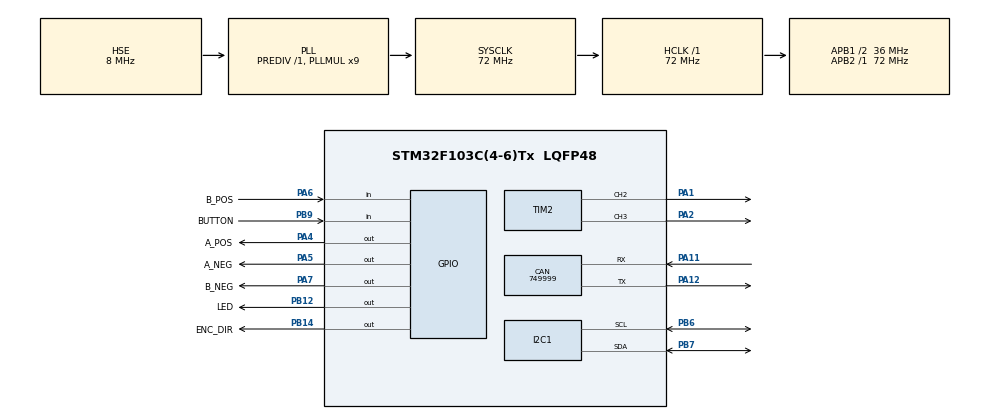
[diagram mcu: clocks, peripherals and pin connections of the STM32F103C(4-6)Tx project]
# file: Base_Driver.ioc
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CAN.BS1=CAN_BS1_1TQ
CAN.BS2=CAN_BS2_1TQ
CAN.CalculateBaudRate=749999
CAN.CalculateTimeBit=1333
CAN.CalculateTimeQuantum=444.44444444444446
Mcu.Family=STM32F1
Mcu.Name=STM32F103C(4-6)Tx
Mcu.Package=LQFP48
NVIC.PriorityGroup=NVIC_PRIORITYGROUP_4
PA1.Signal=S_TIM2_CH2
PA11.Mode=CAN_Activate
PA11.Signal=CAN_RX
PA12.Mode=CAN_Activate
PA12.Signal=CAN_TX
PA13.Mode=Serial_Wire
PA13.Signal=SYS_JTMS-SWDIO
PA14.Mode=Serial_Wire
PA14.Signal=SYS_JTCK-SWCLK
PA2.Signal=S_TIM2_CH3
PA4.GPIO_Label=A_POS
PA4.Signal=GPIO_Output
PA5.GPIO_Label=A_NEG
PA5.Signal=GPIO_Output
PA6.GPIO_Label=B_POS
PA6.Signal=GPIO_Input
PA7.GPIO_Label=B_NEG
PA7.Signal=GPIO_Output
PB12.GPIO_Label=LED
PB12.Signal=GPIO_Output
PB14.GPIO_Label=ENC_DIR
PB14.Signal=GPIO_Output
PB6.Mode=I2C
PB6.Signal=I2C1_SCL
PB7.Mode=I2C
PB7.Signal=I2C1_SDA
PB9.GPIO_Label=BUTTON
PB9.Signal=GPIO_Input
PD0-OSC_IN.Mode=HSE-External-Oscillator
PD0-OSC_IN.Signal=RCC_OSC_IN
PD1-OSC_OUT.Mode=HSE-External-Oscillator
PD1-OSC_OUT.Signal=RCC_OSC_OUT
ProjectManager.HeapSize=0x200
ProjectManager.StackSize=0x400
ProjectManager.TargetToolchain=STM32CubeIDE
RCC.AHBFreq_Value=72000000
RCC.APB1CLKDivider=RCC_HCLK_DIV2
RCC.APB1Freq_Value=36000000
RCC.APB1TimFreq_Value=72000000
RCC.APB2Freq_Value=72000000
RCC.APB2TimFreq_Value=72000000
RCC.HCLKFreq_Value=72000000
RCC.PLLMUL=RCC_PLL_MUL9
RCC.PLLSourceVirtual=RCC_PLLSOURCE_HSE
RCC.SYSCLKFreq_VALUE=72000000
RCC.SYSCLKSource=RCC_SYSCLKSOURCE_PLLCLK
RCC.USBFreq_Value=72000000
SH.S_TIM2_CH2.0=TIM2_CH2,PWM Generation2 CH2
SH.S_TIM2_CH3.0=TIM2_CH3,PWM Generation3 CH3
TIM2.Channel-PWM\ Generation2\ CH2=TIM_CHANNEL_2
TIM2.Channel-PWM\ Generation3\ CH3=TIM_CHANNEL_3
VP_TIM2_VS_ClockSourceINT.Mode=Internal
board=custom

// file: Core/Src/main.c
/* USER CODE BEGIN Header */
/**
  ******************************************************************************
  * @file           : main.c
  * @brief          : Main program body
  ******************************************************************************
  * @attention
  *
  * Copyright (c) 2024 STMicroelectronics.
  * All rights reserved.
  *
  * This software is licensed under terms that can be found in the LICENSE file
  * in the root directory of this software component.
  * If no LICENSE file comes with this software, it is provided AS-IS.
  *
  ******************************************************************************
  */
/* USER CODE END Header */
#include "main.h"
#include "as5600.h"
#include <string.h>

CAN_HandleTypeDef hcan;

I2C_HandleTypeDef hi2c1;

TIM_HandleTypeDef htim2;

void SystemClock_Config(void);
static void MX_GPIO_Init(void);
static void MX_CAN_Init(void);
static void MX_I2C1_Init(void);
static void MX_TIM2_Init(void);

int main(void)
{

  /* USER CODE BEGIN 1 */
	float angle = 0;
  /* USER CODE END 1 */

  /* MCU Configuration--------------------------------------------------------*/

  /* Reset of all peripherals, Initializes the Flash interface and the Systick. */
  HAL_Init();

  /* Configure the system clock */
  SystemClock_Config();

  /* Initialize all configured peripherals */
  MX_GPIO_Init();
  MX_CAN_Init();
  MX_I2C1_Init();
  MX_TIM2_Init();

  /* Infinite loop */
  while (1)
  {
	  angle = AS5600_Angle(&hi2c1);

	  HAL_Delay(500);
  }
}

void SystemClock_Config(void)
{
  RCC_OscInitTypeDef RCC_OscInitStruct = {0};
  RCC_ClkInitTypeDef RCC_ClkInitStruct = {0};

  /** Initializes the RCC Oscillators according to the specified parameters
  * in the RCC_OscInitTypeDef structure.
  */
  RCC_OscInitStruct.OscillatorType = RCC_OSCILLATORTYPE_HSE;
  RCC_OscInitStruct.HSEState = RCC_HSE_ON;
  RCC_OscInitStruct.HSEPredivValue = RCC_HSE_PREDIV_DIV1;
  RCC_OscInitStruct.HSIState = RCC_HSI_ON;
  RCC_OscInitStruct.PLL.PLLState = RCC_PLL_ON;
  RCC_OscInitStruct.PLL.PLLSource = RCC_PLLSOURCE_HSE;
  RCC_OscInitStruct.PLL.PLLMUL = RCC_PLL_MUL9;
  if (HAL_RCC_OscConfig(&RCC_OscInitStruct) != HAL_OK)
  {
    Error_Handler();
  }

  /** Initializes the CPU, AHB and APB buses clocks
  */
  RCC_ClkInitStruct.ClockType = RCC_CLOCKTYPE_HCLK|RCC_CLOCKTYPE_SYSCLK
                              |RCC_CLOCKTYPE_PCLK1|RCC_CLOCKTYPE_PCLK2;
  RCC_ClkInitStruct.SYSCLKSource = RCC_SYSCLKSOURCE_PLLCLK;
  RCC_ClkInitStruct.AHBCLKDivider = RCC_SYSCLK_DIV1;
  RCC_ClkInitStruct.APB1CLKDivider = RCC_HCLK_DIV2;
  RCC_ClkInitStruct.APB2CLKDivider = RCC_HCLK_DIV1;

  if (HAL_RCC_ClockConfig(&RCC_ClkInitStruct, FLASH_LATENCY_2) != HAL_OK)
  {
    Error_Handler();
  }
}

static void MX_CAN_Init(void)
{

  hcan.Instance = CAN1;
  hcan.Init.Prescaler = 16;
  hcan.Init.Mode = CAN_MODE_NORMAL;
  hcan.Init.SyncJumpWidth = CAN_SJW_1TQ;
  hcan.Init.TimeSeg1 = CAN_BS1_1TQ;
  hcan.Init.TimeSeg2 = CAN_BS2_1TQ;
  hcan.Init.TimeTriggeredMode = DISABLE;
  hcan.Init.AutoBusOff = DISABLE;
  hcan.Init.AutoWakeUp = DISABLE;
  hcan.Init.AutoRetransmission = DISABLE;
  hcan.Init.ReceiveFifoLocked = DISABLE;
  hcan.Init.TransmitFifoPriority = DISABLE;
  if (HAL_CAN_Init(&hcan) != HAL_OK)
  {
    Error_Handler();
  }

}

static void MX_I2C1_Init(void)
{

  hi2c1.Instance = I2C1;
  hi2c1.Init.ClockSpeed = 400000;
  hi2c1.Init.DutyCycle = I2C_DUTYCYCLE_2;
  hi2c1.Init.OwnAddress1 = 0;
  hi2c1.Init.AddressingMode = I2C_ADDRESSINGMODE_7BIT;
  hi2c1.Init.DualAddressMode = I2C_DUALADDRESS_DISABLE;
  hi2c1.Init.OwnAddress2 = 0;
  hi2c1.Init.GeneralCallMode = I2C_GENERALCALL_DISABLE;
  hi2c1.Init.NoStretchMode = I2C_NOSTRETCH_DISABLE;
  if (HAL_I2C_Init(&hi2c1) != HAL_OK)
  {
    Error_Handler();
  }

}

static void MX_TIM2_Init(void)
{

  TIM_ClockConfigTypeDef sClockSourceConfig = {0};
  TIM_MasterConfigTypeDef sMasterConfig = {0};
  TIM_OC_InitTypeDef sConfigOC = {0};

  htim2.Instance = TIM2;
  htim2.Init.Prescaler = 0;
  htim2.Init.CounterMode = TIM_COUNTERMODE_UP;
  htim2.Init.Period = 65535;
  htim2.Init.ClockDivision = TIM_CLOCKDIVISION_DIV1;
  htim2.Init.AutoReloadPreload = TIM_AUTORELOAD_PRELOAD_DISABLE;
  if (HAL_TIM_Base_Init(&htim2) != HAL_OK)
  {
    Error_Handler();
  }
  sClockSourceConfig.ClockSource = TIM_CLOCKSOURCE_INTERNAL;
  if (HAL_TIM_ConfigClockSource(&htim2, &sClockSourceConfig) != HAL_OK)
  {
    Error_Handler();
  }
  if (HAL_TIM_PWM_Init(&htim2) != HAL_OK)
  {
    Error_Handler();
  }
  sMasterConfig.MasterOutputTrigger = TIM_TRGO_RESET;
  sMasterConfig.MasterSlaveMode = TIM_MASTERSLAVEMODE_DISABLE;
  if (HAL_TIMEx_MasterConfigSynchronization(&htim2, &sMasterConfig) != HAL_OK)
  {
    Error_Handler();
  }
  sConfigOC.OCMode = TIM_OCMODE_PWM1;
  sConfigOC.Pulse = 0;
  sConfigOC.OCPolarity = TIM_OCPOLARITY_HIGH;
  sConfigOC.OCFastMode = TIM_OCFAST_DISABLE;
  if (HAL_TIM_PWM_ConfigChannel(&htim2, &sConfigOC, TIM_CHANNEL_2) != HAL_OK)
  {
    Error_Handler();
  }
  if (HAL_TIM_PWM_ConfigChannel(&htim2, &sConfigOC, TIM_CHANNEL_3) != HAL_OK)
  {
    Error_Handler();
  }
  HAL_TIM_MspPostInit(&htim2);

}

static void MX_GPIO_Init(void)
{
  GPIO_InitTypeDef GPIO_InitStruct = {0};

  /* GPIO Ports Clock Enable */
  __HAL_RCC_GPIOD_CLK_ENABLE();
  __HAL_RCC_GPIOA_CLK_ENABLE();
  __HAL_RCC_GPIOB_CLK_ENABLE();

  /*Configure GPIO pin Output Level */
  HAL_GPIO_WritePin(GPIOA, A_POS_Pin|A_NEG_Pin|B_NEG_Pin, GPIO_PIN_RESET);

  /*Configure GPIO pin Output Level */
  HAL_GPIO_WritePin(GPIOB, LED_Pin|ENC_DIR_Pin, GPIO_PIN_RESET);

  /*Configure GPIO pins : A_POS_Pin A_NEG_Pin B_NEG_Pin */
  GPIO_InitStruct.Pin = A_POS_Pin|A_NEG_Pin|B_NEG_Pin;
  GPIO_InitStruct.Mode = GPIO_MODE_OUTPUT_PP;
  GPIO_InitStruct.Pull = GPIO_NOPULL;
  GPIO_InitStruct.Speed = GPIO_SPEED_FREQ_LOW;
  HAL_GPIO_Init(GPIOA, &GPIO_InitStruct);

  /*Configure GPIO pin : B_POS_Pin */
  GPIO_InitStruct.Pin = B_POS_Pin;
  GPIO_InitStruct.Mode = GPIO_MODE_INPUT;
  GPIO_InitStruct.Pull = GPIO_NOPULL;
  HAL_GPIO_Init(B_POS_GPIO_Port, &GPIO_InitStruct);

  /*Configure GPIO pins : LED_Pin ENC_DIR_Pin */
  GPIO_InitStruct.Pin = LED_Pin|ENC_DIR_Pin;
  GPIO_InitStruct.Mode = GPIO_MODE_OUTPUT_PP;
  GPIO_InitStruct.Pull = GPIO_NOPULL;
  GPIO_InitStruct.Speed = GPIO_SPEED_FREQ_LOW;
  HAL_GPIO_Init(GPIOB, &GPIO_InitStruct);

  /*Configure GPIO pin : BUTTON_Pin */
  GPIO_InitStruct.Pin = BUTTON_Pin;
  GPIO_InitStruct.Mode = GPIO_MODE_INPUT;
  GPIO_InitStruct.Pull = GPIO_NOPULL;
  HAL_GPIO_Init(BUTTON_GPIO_Port, &GPIO_InitStruct);

}

void Error_Handler(void)
{
  __disable_irq();
  while (1)
  {
  }
}
